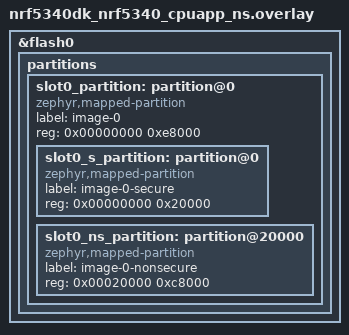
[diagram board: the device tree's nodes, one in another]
/*
 * Copyright (c) 2026 Nordic Semiconductor ASA
 *
 * SPDX-License-Identifier: LicenseRef-Nordic-5-Clause
 */

/* Rebalance secure/non-secure subpartitions to fit larger mesh sample image.
 * MCUboot is removed; slot0 starts at 0x0 and spans 928 KB (0xe8000).
 * Secure: 128 KB, Non-secure: 800 KB.
 */

/delete-node/ &boot_partition;
/delete-node/ &slot0_partition;

&flash0 {
	partitions {
		slot0_partition: partition@0 {
			compatible = "zephyr,mapped-partition";
			label = "image-0";
			reg = <0x00000000 0xe8000>;
			ranges = <0x0 0x0 0xe8000>;
			#address-cells = <1>;
			#size-cells = <1>;

			slot0_s_partition: partition@0 {
				compatible = "zephyr,mapped-partition";
				label = "image-0-secure";
				reg = <0x00000000 0x20000>;
			};

			slot0_ns_partition: partition@20000 {
				compatible = "zephyr,mapped-partition";
				label = "image-0-nonsecure";
				reg = <0x00020000 0xc8000>;
			};
		};
	};
};
